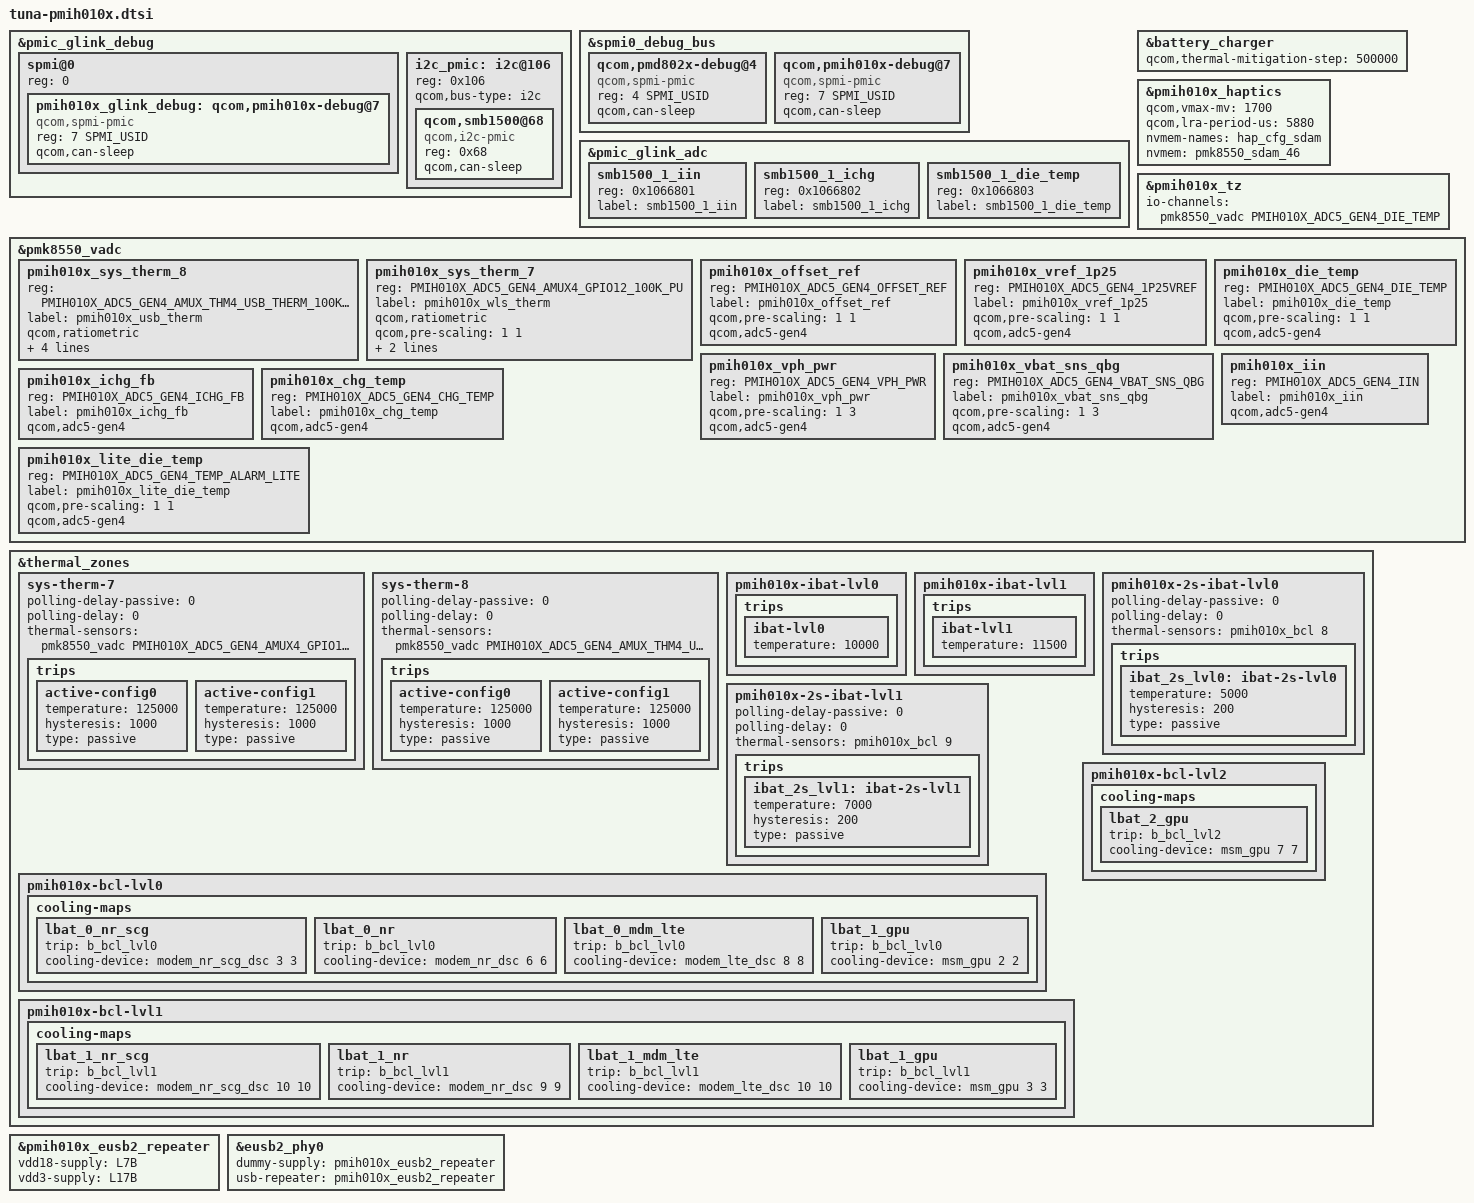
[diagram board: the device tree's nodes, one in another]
// SPDX-License-Identifier: BSD-3-Clause
/*
 * Copyright (c) 2024-2025 Qualcomm Innovation Center, Inc. All rights reserved.
 */

#include "pmih010x.dtsi"
#include <dt-bindings/iio/qcom,spmi-vadc.h>
#include <dt-bindings/iio/qcom,spmi-adc5-gen4-pmih010x.h>

&pmic_glink_debug {
	spmi@0 {
		reg = <0>;
		#address-cells = <2>;
		#size-cells = <0>;

		pmih010x_glink_debug: qcom,pmih010x-debug@7 {
			compatible = "qcom,spmi-pmic";
			reg = <7 SPMI_USID>;
			qcom,can-sleep;
		};
	};

	i2c_pmic:i2c@106 {
		reg = <0x106>;  /* I2C instance 6 in ADSP for SE5 */
		#address-cells = <1>;
		#size-cells = <0>;
		qcom,bus-type = "i2c";

		qcom,smb1500@68 {
			compatible = "qcom,i2c-pmic";
			reg = <0x68>;
			qcom,can-sleep;
		};
	};
};

&spmi0_debug_bus {
	qcom,pmd802x-debug@4 {
		compatible = "qcom,spmi-pmic";
		reg = <4 SPMI_USID>;
		#address-cells = <2>;
		#size-cells = <0>;
		qcom,can-sleep;
	};

	qcom,pmih010x-debug@7 {
		compatible = "qcom,spmi-pmic";
		reg = <7 SPMI_USID>;
		#address-cells = <2>;
		#size-cells = <0>;
		qcom,can-sleep;
	};
};

&pmic_glink_adc {
	status = "ok";

	smb1500_1_iin {
		reg = <0x1066801>;
		label = "smb1500_1_iin";
	};

	smb1500_1_ichg {
		reg = <0x1066802>;
		label = "smb1500_1_ichg";
	};

	smb1500_1_die_temp {
		reg = <0x1066803>;
		label = "smb1500_1_die_temp";
	};
};

&battery_charger {
	qcom,thermal-mitigation-step = <500000>;
	#cooling-cells = <2>;
};

&pmih010x_haptics {
	qcom,vmax-mv = <1700>;
	qcom,lra-period-us = <5880>;
	nvmem-names = "hap_cfg_sdam";
	nvmem = <&pmk8550_sdam_46>;
};

&pmih010x_tz {
	io-channels = <&pmk8550_vadc PMIH010X_ADC5_GEN4_DIE_TEMP>;
	io-channel-names = "thermal";
};

&pmk8550_vadc {
	pmih010x_sys_therm_8 {
		reg = <PMIH010X_ADC5_GEN4_AMUX_THM4_USB_THERM_100K_PU>;
		label = "pmih010x_usb_therm";
		qcom,ratiometric;
		qcom,hw-settle-time = <200>;
		qcom,pre-scaling = <1 1>;
		qcom,adc-tm-type = <1>;
		qcom,adc5-gen4;
	};

	pmih010x_sys_therm_7 {
		reg = <PMIH010X_ADC5_GEN4_AMUX4_GPIO12_100K_PU>;
		label = "pmih010x_wls_therm";
		qcom,ratiometric;
		qcom,pre-scaling = <1 1>;
		qcom,adc-tm-type = <1>;
		qcom,adc5-gen4;
	};

	pmih010x_offset_ref {
		reg = <PMIH010X_ADC5_GEN4_OFFSET_REF>;
		label = "pmih010x_offset_ref";
		qcom,pre-scaling = <1 1>;
		qcom,adc5-gen4;
	};

	pmih010x_vref_1p25 {
		reg = <PMIH010X_ADC5_GEN4_1P25VREF>;
		label = "pmih010x_vref_1p25";
		qcom,pre-scaling = <1 1>;
		qcom,adc5-gen4;
	};

	pmih010x_die_temp {
		reg = <PMIH010X_ADC5_GEN4_DIE_TEMP>;
		label = "pmih010x_die_temp";
		qcom,pre-scaling = <1 1>;
		qcom,adc5-gen4;
	};

	pmih010x_vph_pwr {
		reg = <PMIH010X_ADC5_GEN4_VPH_PWR>;
		label = "pmih010x_vph_pwr";
		qcom,pre-scaling = <1 3>;
		qcom,adc5-gen4;
	};

	pmih010x_vbat_sns_qbg {
		reg = <PMIH010X_ADC5_GEN4_VBAT_SNS_QBG>;
		label = "pmih010x_vbat_sns_qbg";
		qcom,pre-scaling = <1 3>;
		qcom,adc5-gen4;
	};

	pmih010x_iin {
		reg = <PMIH010X_ADC5_GEN4_IIN>;
		label = "pmih010x_iin";
		qcom,adc5-gen4;
	};

	pmih010x_ichg_fb {
		reg = <PMIH010X_ADC5_GEN4_ICHG_FB>;
		label = "pmih010x_ichg_fb";
		qcom,adc5-gen4;
	};

	pmih010x_chg_temp {
		reg = <PMIH010X_ADC5_GEN4_CHG_TEMP>;
		label = "pmih010x_chg_temp";
		qcom,adc5-gen4;
	};

	pmih010x_lite_die_temp {
		reg = <PMIH010X_ADC5_GEN4_TEMP_ALARM_LITE>;
		label = "pmih010x_lite_die_temp";
		qcom,pre-scaling = <1 1>;
		qcom,adc5-gen4;
	};
};

&thermal_zones {
	sys-therm-7 {
		polling-delay-passive = <0>;
		polling-delay = <0>;
		thermal-sensors = <&pmk8550_vadc PMIH010X_ADC5_GEN4_AMUX4_GPIO12_100K_PU>;
		trips {
			active-config0 {
				temperature = <125000>;
				hysteresis = <1000>;
				type = "passive";
			};

			active-config1 {
				temperature = <125000>;
				hysteresis = <1000>;
				type = "passive";
			};
		};
	};

	sys-therm-8 {
		polling-delay-passive = <0>;
		polling-delay = <0>;
		thermal-sensors = <&pmk8550_vadc PMIH010X_ADC5_GEN4_AMUX_THM4_USB_THERM_100K_PU>;
		trips {
			active-config0 {
				temperature = <125000>;
				hysteresis = <1000>;
				type = "passive";
			};

			active-config1 {
				temperature = <125000>;
				hysteresis = <1000>;
				type = "passive";
			};
		};
	};

	pmih010x-ibat-lvl0 {
		trips {
			ibat-lvl0 {
				temperature = <10000>;
			};
		};
	};

	pmih010x-ibat-lvl1 {
		trips {
			ibat-lvl1 {
				temperature = <11500>;
			};
		};
	};

	pmih010x-2s-ibat-lvl0 {
		polling-delay-passive = <0>;
		polling-delay = <0>;
		thermal-sensors = <&pmih010x_bcl 8>;

		trips {
			ibat_2s_lvl0: ibat-2s-lvl0 {
				temperature = <5000>;
				hysteresis = <200>;
				type = "passive";
			};
		};
	};

	pmih010x-2s-ibat-lvl1 {
		polling-delay-passive = <0>;
		polling-delay = <0>;
		thermal-sensors = <&pmih010x_bcl 9>;

		trips {
			ibat_2s_lvl1: ibat-2s-lvl1 {
				temperature = <7000>;
				hysteresis = <200>;
				type = "passive";
			};
		};
	};

	pmih010x-bcl-lvl0 {
		cooling-maps {
			lbat_0_nr_scg {
				trip = <&b_bcl_lvl0>;
				cooling-device = <&modem_nr_scg_dsc 3 3>;
			};

			lbat_0_nr {
				trip = <&b_bcl_lvl0>;
				cooling-device = <&modem_nr_dsc 6 6>;
			};

			lbat_0_mdm_lte {
				trip = <&b_bcl_lvl0>;
				cooling-device = <&modem_lte_dsc 8 8>;
			};

			lbat_1_gpu {
				trip = <&b_bcl_lvl0>;
				cooling-device = <&msm_gpu 2 2>;
			};
		};
	};

	pmih010x-bcl-lvl1 {
		cooling-maps {
			lbat_1_nr_scg {
				trip = <&b_bcl_lvl1>;
				cooling-device = <&modem_nr_scg_dsc 10 10>;
			};

			lbat_1_nr {
				trip = <&b_bcl_lvl1>;
				cooling-device = <&modem_nr_dsc 9 9>;
			};

			lbat_1_mdm_lte {
				trip = <&b_bcl_lvl1>;
				cooling-device = <&modem_lte_dsc 10 10>;
			};

			lbat_1_gpu {
				trip = <&b_bcl_lvl1>;
				cooling-device = <&msm_gpu 3 3>;
			};
		};
	};

	pmih010x-bcl-lvl2 {
		cooling-maps {
			lbat_2_gpu {
				trip = <&b_bcl_lvl2>;
				cooling-device = <&msm_gpu 7 7>;
			};
		};
	};

};

&pmih010x_eusb2_repeater {
	vdd18-supply = <&L7B>;
	vdd3-supply = <&L17B>;
};

&eusb2_phy0 {
	dummy-supply = <&pmih010x_eusb2_repeater>;
	usb-repeater = <&pmih010x_eusb2_repeater>;
};
